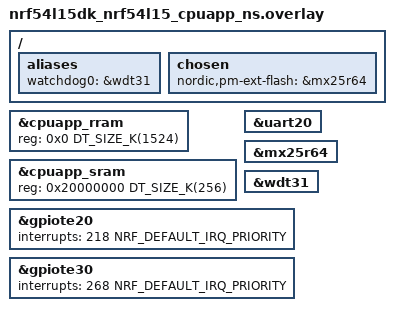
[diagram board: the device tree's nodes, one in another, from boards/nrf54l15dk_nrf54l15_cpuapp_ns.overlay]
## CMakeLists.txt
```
#
# Copyright (c) 2023 Nordic Semiconductor ASA
#
# SPDX-License-Identifier: LicenseRef-Nordic-5-Clause
#

cmake_minimum_required(VERSION 3.20.0)

find_package(Zephyr HINTS $ENV{ZEPHYR_BASE})

project(matter-template)

# Enable GNU STD support.
include(${ZEPHYR_CONNECTEDHOMEIP_MODULE_DIR}/config/nrfconnect/app/enable-gnu-std.cmake)

# NORDIC SDK APP START

# Include all source files that are located in the Matter common directory.
include(${ZEPHYR_NRF_MODULE_DIR}/samples/matter/common/cmake/source_common.cmake)

# Include Data Model utils
include(${ZEPHYR_NRF_MODULE_DIR}/samples/matter/common/cmake/data_model.cmake)

include(${ZEPHYR_NRF_MODULE_DIR}/samples/matter/common/cmake/zap_helpers.cmake)
ncs_get_zap_parent_dir(ZAP_PARENT_DIR)

target_include_directories(app PRIVATE
  src
  ${ZAP_PARENT_DIR}
)

target_sources(app PRIVATE
  src/app_task.cpp
  src/main.cpp
  src/temp_sensor_manager.cpp
  src/temperature_manager.cpp
  src/temperature_measurement/sensor.cpp
  src/zcl_callbacks.cpp
  ${ZEPHYR_NRF_MODULE_DIR}/samples/matter/common/src/binding/binding_handler.cpp
)

ncs_configure_data_model()
# NORDIC SDK APP END
```

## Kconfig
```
#
# Copyright (c) 2023 Nordic Semiconductor
#
# SPDX-License-Identifier: LicenseRef-Nordic-5-Clause
#
mainmenu "Matter Thermostat sample application"

config THERMOSTAT_TEMPERATURE_STEP
	int "Defines a simulated temperature step. Use 0 for random"
	default 0
	help
	  A temperature step that defines differences between consecutive simulated temperature measurements. If set to 0, then the step is random.

config THERMOSTAT_SIMULATED_TEMPERATURE_MAX
	int "Maximum simulated temperature value"
	default 3000

config THERMOSTAT_SIMULATED_TEMPERATURE_MIN
	int "Minimum simulated temperature value"
	default 1500

config THERMOSTAT_SIMULATED_TEMPERATURE_CHANGE
	bool "Select to set the temperature to rise or fall"
	default y
	help
	  If set to true, the simulated temperature is rising. If set to false, the simulated temperature is falling.

# Enable Read Client functionality for all build configurations.
config CHIP_ENABLE_READ_CLIENT
	default y

# Sample configuration used for Thread networking
if OPENTHREAD

choice OPENTHREAD_NORDIC_LIBRARY_CONFIGURATION
	default OPENTHREAD_NORDIC_LIBRARY_MTD
endchoice

choice OPENTHREAD_DEVICE_TYPE
	default OPENTHREAD_MTD
endchoice

endif # OPENTHREAD

config CHIP_WIFI
	default y if BOARD_NRF7002DK_NRF5340_CPUAPP || SHIELD_NRF7002EB2
	select DEPRECATED if SOC_SERIES_NRF53X

source "$(ZEPHYR_CONNECTEDHOMEIP_MODULE_DIR)/config/nrfconnect/chip-module/Kconfig.features"
source "$(ZEPHYR_CONNECTEDHOMEIP_MODULE_DIR)/config/nrfconnect/chip-module/Kconfig.defaults"
source "$(ZEPHYR_NRF_MODULE_DIR)/samples/matter/common/src/Kconfig"
source "Kconfig.zephyr"
```

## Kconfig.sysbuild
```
#
# Copyright (c) 2023 Nordic Semiconductor ASA
#
# SPDX-License-Identifier: LicenseRef-Nordic-5-Clause
#

# This config has to be enabled manually for variants with shields, because sysbuild does not support it.
config WIFI_NRF70
	default y if BOARD_NRF7002DK

#### Radio core selection
config NRF_DEFAULT_IPC_RADIO
	default y

# Enable IEEE802.15.4 serialization to network core
# This config automatically pulls in the `overlay-802154.conf` in the ipc_radio image
config NETCORE_IPC_RADIO_IEEE802154
	default y if SOC_SERIES_NRF53X && !WIFI_NRF70

# Enable Bluetooth serialization to network core
# This config automatically pulls in the `overlay-bt_hci_ipc.conf` in the ipc_radio image
config NETCORE_IPC_RADIO_BT_HCI_IPC
	default y if SOC_SERIES_NRF53X

#### Bootloader
choice BOOTLOADER
	default BOOTLOADER_MCUBOOT
endchoice

if BOOTLOADER_MCUBOOT

#### DFU multi-image support
config DFU_MULTI_IMAGE_PACKAGE_BUILD
	default y

config DFU_MULTI_IMAGE_PACKAGE_APP
	default y

config PM_EXTERNAL_FLASH_MCUBOOT_SECONDARY
	default y

#### DFU network core configuration
if SOC_SERIES_NRF53X

choice MCUBOOT_MODE
	default MCUBOOT_MODE_OVERWRITE_ONLY
endchoice

choice BOOT_SIGNATURE_TYPE
	default BOOT_SIGNATURE_TYPE_RSA
endchoice

config SECURE_BOOT_NETCORE
	default y

config NETCORE_APP_UPDATE
	default y

config DFU_MULTI_IMAGE_PACKAGE_NET
	default y

endif # SOC_SERIES_NRF53X

if BOARD_NRF54L15DK || BOARD_NRF54LM20DK || BOARD_XIAO_NRF54LM20A

# Disable checking the external drivers for nRF54L15 and nRF54LM20 DKs.
config PM_OVERRIDE_EXTERNAL_DRIVER_CHECK
	default y

endif # BOARD_NRF54L15DK || BOARD_NRF54LM20DK || BOARD_XIAO_NRF54LM20A

endif # BOOTLOADER_MCUBOOT

#### Enable generating factory data
config MATTER_FACTORY_DATA_GENERATE
	default y if !BOARD_XIAO_NRF54LM20A

# Store the Wi-Fi firmware patch on external flash by default for nRF5340 with nRF7002
if WIFI_NRF70 && SOC_NRF5340_CPUAPP

choice WIFI_PATCHES_EXT_FLASH_SUPPORT
	default WIFI_PATCHES_EXT_FLASH_STORE

endchoice

config DFU_MULTI_IMAGE_PACKAGE_WIFI_FW_PATCH
	default y

endif # WIFI_NRF70

source "share/sysbuild/Kconfig"
```

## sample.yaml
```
sample:
  description: Matter Thermostat sample
  name: Matter Thermostat
common:
  tags:
    - sysbuild
    - ci_samples_matter
tests:
  sample.matter.thermostat.debug:
    sysbuild: true
    build_only: true
    integration_platforms:
      - nrf52840dk/nrf52840
      - nrf5340dk/nrf5340/cpuapp
      - nrf7002dk/nrf5340/cpuapp
      - nrf54l15dk/nrf54l15/cpuapp
      - nrf54l15dk/nrf54l15/cpuapp/ns
      - nrf54lm20dk/nrf54lm20a/cpuapp
    platform_allow:
      - nrf52840dk/nrf52840
      - nrf5340dk/nrf5340/cpuapp
      - nrf7002dk/nrf5340/cpuapp
      - nrf54l15dk/nrf54l15/cpuapp
      - nrf54l15dk/nrf54l15/cpuapp/ns
      - nrf54lm20dk/nrf54lm20a/cpuapp
  sample.matter.thermostat.nrf7002eb2.debug:
    sysbuild: true
    build_only: true
    extra_args:
      - thermostat_SHIELD=nrf7002eb2
      - SB_CONFIG_WIFI_NRF70=y
    integration_platforms:
      - nrf54lm20dk/nrf54lm20a/cpuapp
    platform_allow:
      - nrf54lm20dk/nrf54lm20a/cpuapp
  sample.matter.thermostat.release:
    sysbuild: true
    build_only: true
    extra_args:
      - FILE_SUFFIX=release
      - SB_CONFIG_BOOTLOADER_MCUBOOT=y
      - SB_CONFIG_PARTITION_MANAGER=y
    integration_platforms:
      - nrf52840dk/nrf52840
      - nrf5340dk/nrf5340/cpuapp
      - nrf7002dk/nrf5340/cpuapp
      - nrf54l15dk/nrf54l15/cpuapp
      - nrf54lm20dk/nrf54lm20a/cpuapp
    platform_allow:
      - nrf52840dk/nrf52840
      - nrf5340dk/nrf5340/cpuapp
      - nrf7002dk/nrf5340/cpuapp
      - nrf54l15dk/nrf54l15/cpuapp
      - nrf54lm20dk/nrf54lm20a/cpuapp
  sample.matter.thermostat.nrf7002eb2.release:
    sysbuild: true
    build_only: true
    extra_args:
      - FILE_SUFFIX=release
      - SB_CONFIG_BOOTLOADER_MCUBOOT=y
      - SB_CONFIG_PARTITION_MANAGER=y
      - thermostat_SHIELD=nrf7002eb2
      - SB_CONFIG_WIFI_NRF70=y
    integration_platforms:
      - nrf54lm20dk/nrf54lm20a/cpuapp
    platform_allow:
      - nrf54lm20dk/nrf54lm20a/cpuapp
```

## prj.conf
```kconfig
#
# Copyright (c) 2023 Nordic Semiconductor ASA
#
# SPDX-License-Identifier: LicenseRef-Nordic-5-Clause
#

# This sample uses Kconfig.defaults to set options common for all
# samples. This file should contain only options specific for this sample
# or overrides of default values.

# Enable CHIP
CONFIG_CHIP=y
CONFIG_CHIP_PROJECT_CONFIG="src/chip_project_config.h"
CONFIG_CHIP_DEVICE_PRODUCT_NAME="Matter Thermostat"

# Configure ZAP file name
CONFIG_NCS_SAMPLE_MATTER_ZAP_FILE_PATH="${APPLICATION_CONFIG_DIR}/src/default_zap/thermostat.zap"

# 32782 == 0x800e (example thermostat product)
CONFIG_CHIP_DEVICE_PRODUCT_ID=32782
CONFIG_STD_CPP17=y

# Enable Matter pairing automatically on application start.
CONFIG_CHIP_ENABLE_PAIRING_AUTOSTART=y

# Enable Matter extended announcement and increase duration to 1 hour.
CONFIG_CHIP_BLE_EXT_ADVERTISING=y
CONFIG_CHIP_BLE_ADVERTISING_DURATION=60

# Add support for LEDs and buttons on Nordic development kits
CONFIG_DK_LIBRARY=y

# Bluetooth Low Energy configuration
CONFIG_BT_DEVICE_NAME="MatterThermo"

# Other settings
CONFIG_THREAD_NAME=y
CONFIG_MPU_STACK_GUARD=y
CONFIG_RESET_ON_FATAL_ERROR=n
CONFIG_CHIP_LIB_SHELL=y
CONFIG_NCS_SAMPLE_MATTER_TEST_SHELL=y

# Disable NFC onboarding
CONFIG_CHIP_NFC_ONBOARDING_PAYLOAD=y

# Reduce application size
CONFIG_USE_SEGGER_RTT=n

# Enable Factory Data feature
CONFIG_CHIP_FACTORY_DATA=y
CONFIG_CHIP_FACTORY_DATA_BUILD=y
```

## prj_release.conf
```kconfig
#
# Copyright (c) 2023 Nordic Semiconductor ASA
#
# SPDX-License-Identifier: LicenseRef-Nordic-5-Clause
#

# This sample uses Kconfig.defaults to set options common for all
# samples. This file should contain only options specific for this sample
# or overrides of default values.

# Enable CHIP
CONFIG_CHIP=y
CONFIG_CHIP_PROJECT_CONFIG="src/chip_project_config.h"
CONFIG_CHIP_DEVICE_PRODUCT_NAME="Matter Thermostat"

# Configure ZAP file name
CONFIG_NCS_SAMPLE_MATTER_ZAP_FILE_PATH="${APPLICATION_CONFIG_DIR}/src/default_zap/thermostat.zap"

# 32782 == 0x800e (example thermostat product)
CONFIG_CHIP_DEVICE_PRODUCT_ID=32782
CONFIG_STD_CPP17=y

# Enable Matter pairing automatically on application start.
CONFIG_CHIP_ENABLE_PAIRING_AUTOSTART=y

# Enable Matter extended announcement and increase duration to 1 hour.
CONFIG_CHIP_BLE_EXT_ADVERTISING=y
CONFIG_CHIP_BLE_ADVERTISING_DURATION=60

# Add support for LEDs and buttons on Nordic development kits
CONFIG_DK_LIBRARY=y

# Bluetooth Low Energy configuration
CONFIG_BT_DEVICE_NAME="MatterThermo"

# Enable system reset on fatal error
CONFIG_RESET_ON_FATAL_ERROR=y

# Disable all debug features
CONFIG_USE_SEGGER_RTT=n
CONFIG_SHELL=n
CONFIG_OPENTHREAD_SHELL=n
CONFIG_CONSOLE=n
CONFIG_UART_CONSOLE=n
CONFIG_SERIAL=n
CONFIG_LOG=n
CONFIG_LOG_MODE_MINIMAL=n
CONFIG_ASSERT_VERBOSE=n
CONFIG_ASSERT_NO_FILE_INFO=y
CONFIG_PRINTK=n
CONFIG_PRINTK_SYNC=n
CONFIG_THREAD_NAME=n

# Disable NFC onboarding
CONFIG_CHIP_NFC_ONBOARDING_PAYLOAD=n

# Enable Factory Data feature
CONFIG_CHIP_FACTORY_DATA=y
CONFIG_CHIP_FACTORY_DATA_BUILD=y

# Enable Watchdog
CONFIG_NCS_SAMPLE_MATTER_WATCHDOG=y

# Enable LTO to decrease the flash usage.
CONFIG_LTO=y
CONFIG_ISR_TABLES_LOCAL_DECLARATION=y
```

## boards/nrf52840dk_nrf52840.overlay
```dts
/*
 * Copyright (c) 2023 Nordic Semiconductor ASA
 *
 * SPDX-License-Identifier: LicenseRef-Nordic-5-Clause
 */

/ {
	chosen {
		nordic,pm-ext-flash = &mx25r64;
	};
};

/* Disable unused peripherals to reduce power consumption */
&adc {
	status = "disabled";
};
&uart1 {
	status = "disabled";
};
&i2c0 {
	status = "disabled";
};
&pwm0 {
	status = "disabled";
};
&spi1 {
	status = "disabled";
};
&spi3 {
	status = "disabled";
};
&usbd {
	status = "disabled";
};
```

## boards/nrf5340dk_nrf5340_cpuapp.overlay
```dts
/*
 * Copyright (c) 2023 Nordic Semiconductor ASA
 *
 * SPDX-License-Identifier: LicenseRef-Nordic-5-Clause
 */

#include <zephyr/dt-bindings/ipc_service/static_vrings.h>

/ {
	chosen {
		nordic,pm-ext-flash = &mx25r64;
	};
};

/* Set IPC thread priority to the highest value to not collide with other threads. */
&ipc0 {
	zephyr,priority = <0 PRIO_COOP>;
};

/* Disable unused peripherals to reduce power consumption */
&adc {
	status = "disabled";
};
&i2c1 {
	status = "disabled";
};
&pwm0 {
	status = "disabled";
};
&spi2 {
	status = "disabled";
};
&usbd {
	status = "disabled";
};
```

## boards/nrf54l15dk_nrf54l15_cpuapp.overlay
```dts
/*
 * Copyright (c) 2024 Nordic Semiconductor ASA
 *
 * SPDX-License-Identifier: LicenseRef-Nordic-5-Clause
 */

/ {
	aliases {
		/* Use watchdog wdt31 as the application watchdog */
		watchdog0 = &wdt31;
	};

	chosen {
		nordic,pm-ext-flash = &mx25r64;
	};
};

/* restore full RRAM and SRAM space - by default some parts are dedicated to FLRP */
&cpuapp_rram {
	reg = <0x0 DT_SIZE_K(1524)>;
};

&cpuapp_sram {
	reg = <0x20000000 DT_SIZE_K(256)>;
	ranges = <0x0 0x20000000  0x40000>;
};

/* TODO: re-enable HWFC once it's fixed */
&uart20 {
	/delete-property/ hw-flow-control;
};

&mx25r64 {
	status = "okay";
};

&wdt31 {
	status = "okay";
};
```

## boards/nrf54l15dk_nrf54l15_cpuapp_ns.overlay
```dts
/*
 * Copyright (c) 2024 Nordic Semiconductor ASA
 *
 * SPDX-License-Identifier: LicenseRef-Nordic-5-Clause
 */

/ {
	aliases {
		/* Use watchdog wdt31 as the application watchdog */
		watchdog0 = &wdt31;
	};

	chosen {
		nordic,pm-ext-flash = &mx25r64;
	};
};

/* restore full RRAM and SRAM space - by default some parts are dedicated to FLRP */
&cpuapp_rram {
	reg = <0x0 DT_SIZE_K(1524)>;
};

&cpuapp_sram {
	reg = <0x20000000 DT_SIZE_K(256)>;
	ranges = <0x0 0x20000000  0x40000>;
};

/* TODO: re-enable HWFC once it's fixed */
&uart20 {
	/delete-property/ hw-flow-control;
};

&mx25r64 {
	status = "okay";
};

&wdt31 {
	status = "okay";
};

/* Change IRQ ids to handle button interrupts.
 * The default values for nRF54L15 are 219 and 269,
 * but with TF-M they are reserved for the secure domain
 * (218 and 268 are reserved for the non-secure domain).
 */
&gpiote20 {
	interrupts = <218 NRF_DEFAULT_IRQ_PRIORITY>;
};

&gpiote30 {
	interrupts = <268 NRF_DEFAULT_IRQ_PRIORITY>;
};
```

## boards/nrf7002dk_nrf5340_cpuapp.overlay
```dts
/*
 * Copyright (c) 2023 Nordic Semiconductor ASA
 *
 * SPDX-License-Identifier: LicenseRef-Nordic-5-Clause
 */

#include <zephyr/dt-bindings/ipc_service/static_vrings.h>

/ {
	chosen {
		nordic,pm-ext-flash = &mx25r64;
	};

	aliases {
		watchdog0 = &wdt0;
	};

};

/* Set IPC thread priority to the highest value to not collide with other threads. */
&ipc0 {
	zephyr,priority = <0 PRIO_COOP>;
};
```

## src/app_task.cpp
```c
/*
 * Copyright (c) 2023 Nordic Semiconductor ASA
 *
 * SPDX-License-Identifier: LicenseRef-Nordic-5-Clause
 */

#include "app_task.h"

#include "temp_sensor_manager.h"
#include "temperature_manager.h"

#include "app/matter_init.h"
#include "app/task_executor.h"
#include "clusters/identify.h"

#include <app-common/zap-generated/attributes/Accessors.h>
#include <setup_payload/OnboardingCodesUtil.h>

#include <zephyr/logging/log.h>

LOG_MODULE_DECLARE(app, CONFIG_MATTER_LOG_LEVEL);

using namespace ::chip;
using namespace ::chip::app;
using namespace ::chip::DeviceLayer;

namespace
{
constexpr EndpointId kThermostatEndpointId = 1;

Nrf::Matter::IdentifyCluster sIdentifyCluster(kThermostatEndpointId);

#define TEMPERATURE_BUTTON_MASK DK_BTN2_MSK
} /* namespace */

void AppTask::ButtonEventHandler(Nrf::ButtonState state, Nrf::ButtonMask hasChanged)
{
	if (TEMPERATURE_BUTTON_MASK & hasChanged) {
		TemperatureButtonAction action = (TEMPERATURE_BUTTON_MASK & state) ? TemperatureButtonAction::Pushed :
										     TemperatureButtonAction::Released;
		Nrf::PostTask([action] { ThermostatHandler(action); });
	}
}

void AppTask::ThermostatHandler(const TemperatureButtonAction &action)
{
	if (action == TemperatureButtonAction::Pushed) {
		TemperatureManager::Instance().LogThermostatStatus();
	}
}

CHIP_ERROR AppTask::Init()
{
	/* Initialize Matter stack */
	ReturnErrorOnFailure(Nrf::Matter::PrepareServer(Nrf::Matter::InitData{ .mPostServerInitClbk = [] {
		CHIP_ERROR err = TempSensorManager::Instance().Init();
		if (err != CHIP_NO_ERROR) {
			LOG_ERR("TempSensorManager Init fail");
			return err;
		}
		err = TemperatureManager::Instance().Init();
		if (err != CHIP_NO_ERROR) {
			LOG_ERR("TemperatureManager Init fail");
		}
		return err;
	} }));

	if (!Nrf::GetBoard().Init(ButtonEventHandler)) {
		LOG_ERR("User interface initialization failed.");
		return CHIP_ERROR_INCORRECT_STATE;
	}

	/* Register Matter event handler that controls the connectivity status LED based on the captured Matter network
	 * state. */
	ReturnErrorOnFailure(Nrf::Matter::RegisterEventHandler(Nrf::Board::DefaultMatterEventHandler, 0));

	ReturnErrorOnFailure(sIdentifyCluster.Init());

	return Nrf::Matter::StartServer();
}

CHIP_ERROR AppTask::StartApp()
{
	ReturnErrorOnFailure(Init());

	while (true) {
		Nrf::DispatchNextTask();
	}

	return CHIP_NO_ERROR;
}
```

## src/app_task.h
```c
/*
 * Copyright (c) 2023 Nordic Semiconductor ASA
 *
 * SPDX-License-Identifier: LicenseRef-Nordic-5-Clause
 */

#pragma once

#include "board/board.h"

#include <platform/CHIPDeviceLayer.h>

struct Identify;

enum class TemperatureButtonAction : uint8_t { Pushed, Released };

class AppTask {
public:
	static AppTask &Instance()
	{
		static AppTask sAppTask;
		return sAppTask;
	};

	CHIP_ERROR StartApp();

private:
	CHIP_ERROR Init();

	static void ButtonEventHandler(Nrf::ButtonState state, Nrf::ButtonMask hasChanged);
	static void ThermostatHandler(const TemperatureButtonAction &action);
};
```

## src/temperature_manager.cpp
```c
/*
 * Copyright (c) 2023 Nordic Semiconductor ASA
 *
 * SPDX-License-Identifier: LicenseRef-Nordic-5-Clause
 */

#include "temperature_manager.h"
#include <app-common/zap-generated/cluster-objects.h>
#include <platform/PlatformManager.h>
#include <zephyr/logging/log.h>

LOG_MODULE_DECLARE(app, CONFIG_CHIP_APP_LOG_LEVEL);

using namespace chip;
using namespace ::chip::DeviceLayer;
using namespace ::chip::app::Clusters;
using namespace chip::app::Clusters::Thermostat::Attributes;
using namespace Protocols::InteractionModel;

constexpr EndpointId kThermostatEndpoint = 1;

namespace
{

/* Convert and return only complete part of value to printable type */
uint8_t ReturnCompleteValue(int16_t Value)
{
	return static_cast<uint8_t>(Value / 100);
}

/* Converts and returns only reminder part of value to printable type.
 * This formula rounds reminder value to one significant figure
 */

uint8_t ReturnRemainderValue(int16_t Value)
{
	return static_cast<uint8_t>((Value % 100 + 5) / 10);
}

} /* namespace */

CHIP_ERROR TemperatureManager::Init()
{
	CHIP_ERROR err = CHIP_NO_ERROR;

	PlatformMgr().LockChipStack();

	VerifyOrExit(Status::Success == LocalTemperature::Get(kThermostatEndpoint, mLocalTempCelsius),
		     err = CHIP_IM_GLOBAL_STATUS(Failure));
	VerifyOrExit(Status::Success == OutdoorTemperature::Get(kThermostatEndpoint, mOutdoorTempCelsius),
		     err = CHIP_IM_GLOBAL_STATUS(Failure));
	VerifyOrExit(Status::Success == OccupiedCoolingSetpoint::Get(kThermostatEndpoint, &mCoolingCelsiusSetPoint),
		     err = CHIP_IM_GLOBAL_STATUS(Failure));
	VerifyOrExit(Status::Success == OccupiedHeatingSetpoint::Get(kThermostatEndpoint, &mHeatingCelsiusSetPoint),
		     err = CHIP_IM_GLOBAL_STATUS(Failure));
	VerifyOrExit(Status::Success == SystemMode::Get(kThermostatEndpoint, &mThermMode),
		     err = CHIP_IM_GLOBAL_STATUS(Failure));

exit:
	PlatformMgr().UnlockChipStack();

	return err;
}

void TemperatureManager::LogThermostatStatus()
{
	LOG_INF("Thermostat:");
	LOG_INF("	Mode - %d", static_cast<uint8_t>(mThermMode));
	if (!(GetLocalTemp().IsNull())) {
		int16_t tempValue = GetLocalTemp().Value();
		LOG_INF("	LocalTemperature - %d,%d'C", ReturnCompleteValue(tempValue),
			ReturnRemainderValue(tempValue));
	} else {
		LOG_INF("	LocalTemperature - No Value");
	}
	if (!(GetOutdoorTemp().IsNull())) {
		int16_t tempValue = GetOutdoorTemp().Value();
		LOG_INF("	OutdoorTemperature - %d,%d'C", ReturnCompleteValue(tempValue),
			ReturnRemainderValue(tempValue));
	} else {
		LOG_INF("	OutdoorTemperature - No Value");
	}
	LOG_INF("	HeatingSetpoint - %d,%d'C", ReturnCompleteValue(mHeatingCelsiusSetPoint),
		ReturnRemainderValue(mHeatingCelsiusSetPoint));
	LOG_INF("	CoolingSetpoint - %d,%d'C \n", ReturnCompleteValue(mCoolingCelsiusSetPoint),
		ReturnRemainderValue(mCoolingCelsiusSetPoint));
}

void TemperatureManager::AttributeChangeHandler(EndpointId endpointId, AttributeId attributeId, uint8_t *value,
						uint16_t size)
{
	Status status;

	switch (attributeId) {
	case LocalTemperature::Id: {
		status = LocalTemperature::Get(kThermostatEndpoint, mLocalTempCelsius);
		VerifyOrReturn(Status::Success == status,
			       LOG_ERR("Failed to get Thermostat LocalTemperature attribute"));
	} break;

	case OutdoorTemperature::Id: {
		status = OutdoorTemperature::Get(kThermostatEndpoint, mOutdoorTempCelsius);
		VerifyOrReturn(Status::Success == status,
			       LOG_ERR("Failed to get Thermostat OutdoorTemperature attribute"));
	} break;

	case OccupiedCoolingSetpoint::Id: {
		mCoolingCelsiusSetPoint = *reinterpret_cast<int16_t *>(value);
		LOG_INF("Cooling TEMP: %d", mCoolingCelsiusSetPoint);
	} break;

	case OccupiedHeatingSetpoint::Id: {
		mHeatingCelsiusSetPoint = *reinterpret_cast<int16_t *>(value);
		LOG_INF("Heating TEMP %d", mHeatingCelsiusSetPoint);
	} break;

	case SystemMode::Id: {
		mThermMode = static_cast<app::Clusters::Thermostat::SystemModeEnum>(*value);
	} break;

	default: {
		LOG_ERR("Unhandled thermostat attribute %x", attributeId);
		return;
	} break;
	}

	LogThermostatStatus();
}

app::DataModel::Nullable<int16_t> TemperatureManager::GetLocalTemp()
{
	return mLocalTempCelsius;
}

app::DataModel::Nullable<int16_t> TemperatureManager::GetOutdoorTemp()
{
	return mOutdoorTempCelsius;
}
```
